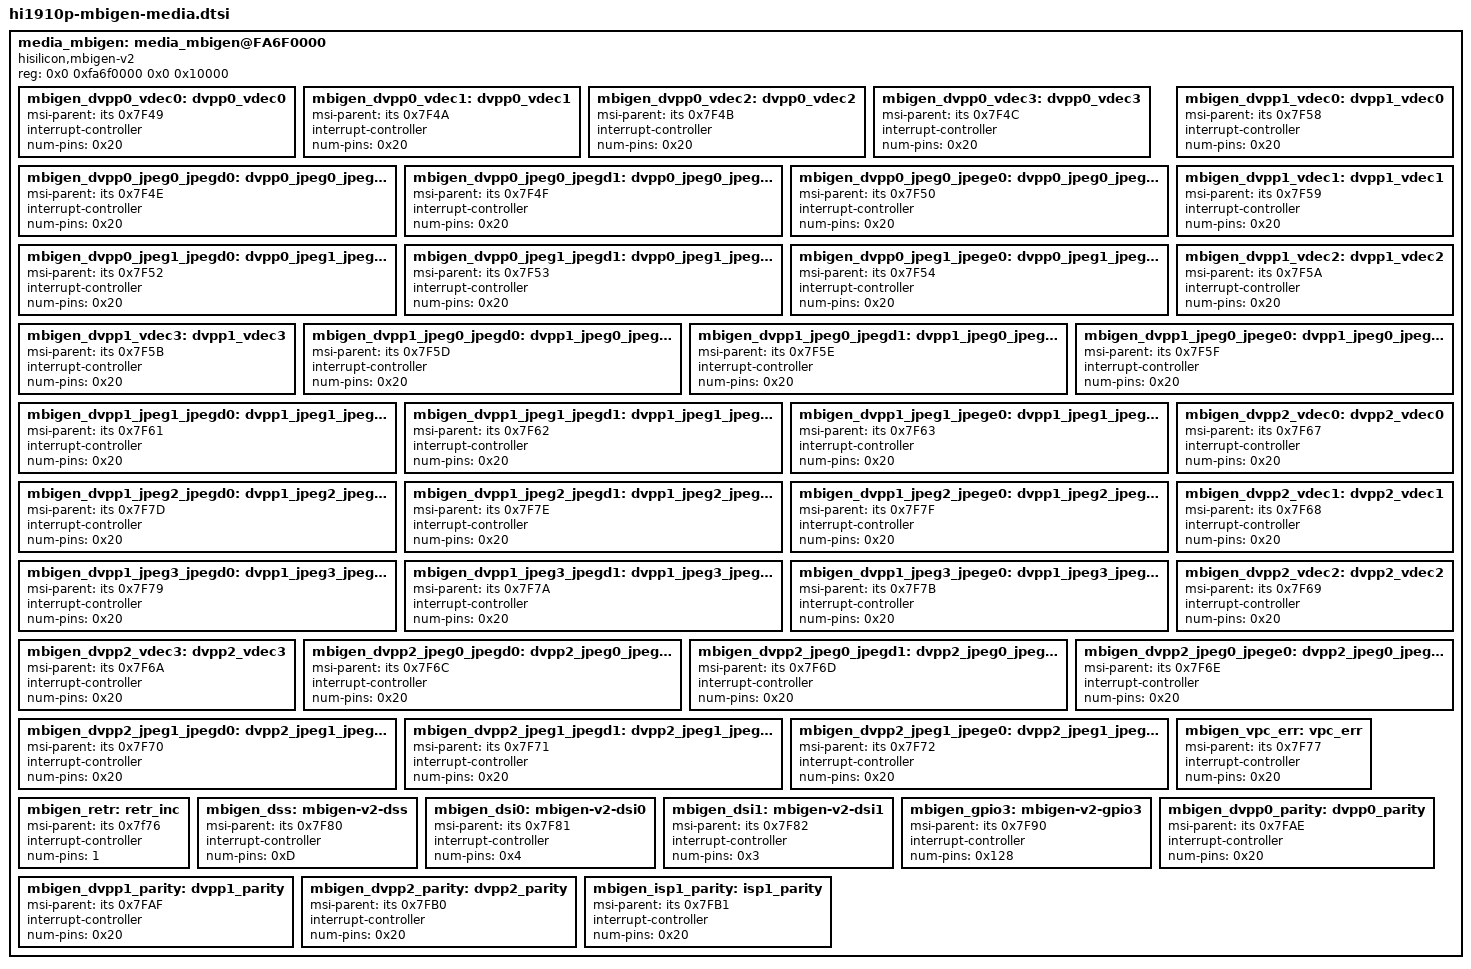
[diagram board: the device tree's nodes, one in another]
/**
* dts file for Hisilicon Ascend Dxxx Development Board
*
* Copyright (C) 2020 Hisilicon Ltd.
*
* This program is free software; you can redistribute it and/or modify
* it under the terms of the GNU General Public License version 2 as
* publishhed by the Free Software Foundation.
*
* Owner：OS
* Author:  c00283067
* Create: Tue Apr 21 20:07:41 EDT 2020
*/
    media_mbigen: media_mbigen@FA6F0000 {
        compatible = "hisilicon,mbigen-v2";
        reg = <0x0 0xfa6f0000 0x0 0x10000>;
        // dvpp 0 vdec
        mbigen_dvpp0_vdec0: dvpp0_vdec0 {
            msi-parent = <&its 0x7F49>;
            interrupt-controller;
            #interrupt-cells = <0x2>;
            num-pins = <0x20>;
        };
        mbigen_dvpp0_vdec1: dvpp0_vdec1 {
            msi-parent = <&its 0x7F4A>;
            interrupt-controller;
            #interrupt-cells = <0x2>;
            num-pins = <0x20>;
        };
        mbigen_dvpp0_vdec2: dvpp0_vdec2 {
            msi-parent = <&its 0x7F4B>;
            interrupt-controller;
            #interrupt-cells = <0x2>;
            num-pins = <0x20>;
        };
        mbigen_dvpp0_vdec3: dvpp0_vdec3 {
            msi-parent = <&its 0x7F4C>;
            interrupt-controller;
            #interrupt-cells = <0x2>;
            num-pins = <0x20>;
        };

        // dvpp 0 jpeg0
        mbigen_dvpp0_jpeg0_jpegd0: dvpp0_jpeg0_jpegd0 {
            msi-parent = <&its 0x7F4E>; // device num: 0x0F5D
            interrupt-controller;
            #interrupt-cells = <0x2>;
            num-pins = <0x20>;
        };
        mbigen_dvpp0_jpeg0_jpegd1: dvpp0_jpeg0_jpegd1 {
            msi-parent = <&its 0x7F4F>; // device num: 0x0F5D
            interrupt-controller;
            #interrupt-cells = <0x2>;
            num-pins = <0x20>;
        };
        mbigen_dvpp0_jpeg0_jpege0: dvpp0_jpeg0_jpege0 {
            msi-parent = <&its 0x7F50>; // device num: 0x0F5F
            interrupt-controller;
            #interrupt-cells = <0x2>;
            num-pins = <0x20>;
        };

        // dvpp 0 jpeg1
        mbigen_dvpp0_jpeg1_jpegd0: dvpp0_jpeg1_jpegd0 {
            msi-parent = <&its 0x7F52>; // device num: 0x0F5D
            interrupt-controller;
            #interrupt-cells = <0x2>;
            num-pins = <0x20>;
        };
        mbigen_dvpp0_jpeg1_jpegd1: dvpp0_jpeg1_jpegd1 {
            msi-parent = <&its 0x7F53>; // device num: 0x0F5D
            interrupt-controller;
            #interrupt-cells = <0x2>;
            num-pins = <0x20>;
        };
        mbigen_dvpp0_jpeg1_jpege0: dvpp0_jpeg1_jpege0 {
            msi-parent = <&its 0x7F54>; // device num: 0x0F5F
            interrupt-controller;
            #interrupt-cells = <0x2>;
            num-pins = <0x20>;
        };

        // dvpp 1 vdec
        mbigen_dvpp1_vdec0: dvpp1_vdec0 {
            msi-parent = <&its 0x7F58>;
            interrupt-controller;
            #interrupt-cells = <0x2>;
            num-pins = <0x20>;
        };
        mbigen_dvpp1_vdec1: dvpp1_vdec1 {
            msi-parent = <&its 0x7F59>;
            interrupt-controller;
            #interrupt-cells = <0x2>;
            num-pins = <0x20>;
        };
        mbigen_dvpp1_vdec2: dvpp1_vdec2 {
            msi-parent = <&its 0x7F5A>;
            interrupt-controller;
            #interrupt-cells = <0x2>;
            num-pins = <0x20>;
        };
        mbigen_dvpp1_vdec3: dvpp1_vdec3 {
            msi-parent = <&its 0x7F5B>;
            interrupt-controller;
            #interrupt-cells = <0x2>;
            num-pins = <0x20>;
        };

        // dvpp1 jpeg0
        mbigen_dvpp1_jpeg0_jpegd0: dvpp1_jpeg0_jpegd0 {
            msi-parent = <&its 0x7F5D>; // device num: 0x0F5D
            interrupt-controller;
            #interrupt-cells = <0x2>;
            num-pins = <0x20>;
        };
        mbigen_dvpp1_jpeg0_jpegd1: dvpp1_jpeg0_jpegd1 {
            msi-parent = <&its 0x7F5E>; // device num: 0x0F5D
            interrupt-controller;
            #interrupt-cells = <0x2>;
            num-pins = <0x20>;
        };
        mbigen_dvpp1_jpeg0_jpege0: dvpp1_jpeg0_jpege0 {
            msi-parent = <&its 0x7F5F>; // device num: 0x0F5F
            interrupt-controller;
            #interrupt-cells = <0x2>;
            num-pins = <0x20>;
        };

        // dvpp 1 jpeg1
        mbigen_dvpp1_jpeg1_jpegd0: dvpp1_jpeg1_jpegd0 {
            msi-parent = <&its 0x7F61>; // device num: 0x0F5D
            interrupt-controller;
            #interrupt-cells = <0x2>;
            num-pins = <0x20>;
        };
        mbigen_dvpp1_jpeg1_jpegd1: dvpp1_jpeg1_jpegd1 {
            msi-parent = <&its 0x7F62>; // device num: 0x0F5D
            interrupt-controller;
            #interrupt-cells = <0x2>;
            num-pins = <0x20>;
        };
        mbigen_dvpp1_jpeg1_jpege0: dvpp1_jpeg1_jpege0 {
            msi-parent = <&its 0x7F63>; // device num: 0x0F5F
            interrupt-controller;
            #interrupt-cells = <0x2>;
            num-pins = <0x20>;
        };

        // dvpp 1 jpeg2
        mbigen_dvpp1_jpeg2_jpegd0: dvpp1_jpeg2_jpegd0 {
            msi-parent = <&its 0x7F7D>; // device num: 0x0F5D
            interrupt-controller;
            #interrupt-cells = <0x2>;
            num-pins = <0x20>;
        };
        mbigen_dvpp1_jpeg2_jpegd1: dvpp1_jpeg2_jpegd1 {
            msi-parent = <&its 0x7F7E>; // device num: 0x0F5D
            interrupt-controller;
            #interrupt-cells = <0x2>;
            num-pins = <0x20>;
        };
        mbigen_dvpp1_jpeg2_jpege0: dvpp1_jpeg2_jpege0 {
            msi-parent = <&its 0x7F7F>; // device num: 0x0F5F
            interrupt-controller;
            #interrupt-cells = <0x2>;
            num-pins = <0x20>;
        };

        // dvpp 1 jpeg3
        mbigen_dvpp1_jpeg3_jpegd0: dvpp1_jpeg3_jpegd0 {
            msi-parent = <&its 0x7F79>; // device num: 0x0F5D
            interrupt-controller;
            #interrupt-cells = <0x2>;
            num-pins = <0x20>;
        };
        mbigen_dvpp1_jpeg3_jpegd1: dvpp1_jpeg3_jpegd1 {
            msi-parent = <&its 0x7F7A>; // device num: 0x0F5D
            interrupt-controller;
            #interrupt-cells = <0x2>;
            num-pins = <0x20>;
        };
        mbigen_dvpp1_jpeg3_jpege0: dvpp1_jpeg3_jpege0 {
            msi-parent = <&its 0x7F7B>; // device num: 0x0F5F
            interrupt-controller;
            #interrupt-cells = <0x2>;
            num-pins = <0x20>;
        };

        // dvpp 2 vdec
        mbigen_dvpp2_vdec0: dvpp2_vdec0 {
            msi-parent = <&its 0x7F67>;
            interrupt-controller;
            #interrupt-cells = <0x2>;
            num-pins = <0x20>;
        };
        mbigen_dvpp2_vdec1: dvpp2_vdec1 {
            msi-parent = <&its 0x7F68>;
            interrupt-controller;
            #interrupt-cells = <0x2>;
            num-pins = <0x20>;
        };
        mbigen_dvpp2_vdec2: dvpp2_vdec2 {
            msi-parent = <&its 0x7F69>;
            interrupt-controller;
            #interrupt-cells = <0x2>;
            num-pins = <0x20>;
        };
        mbigen_dvpp2_vdec3: dvpp2_vdec3 {
            msi-parent = <&its 0x7F6A>;
            interrupt-controller;
            #interrupt-cells = <0x2>;
            num-pins = <0x20>;
        };

        // dvpp2 jpeg0
        mbigen_dvpp2_jpeg0_jpegd0: dvpp2_jpeg0_jpegd0 {
            msi-parent = <&its 0x7F6C>; // device num: 0x0F5D
            interrupt-controller;
            #interrupt-cells = <0x2>;
            num-pins = <0x20>;
        };
        mbigen_dvpp2_jpeg0_jpegd1: dvpp2_jpeg0_jpegd1 {
            msi-parent = <&its 0x7F6D>; // device num: 0x0F5D
            interrupt-controller;
            #interrupt-cells = <0x2>;
            num-pins = <0x20>;
        };
        mbigen_dvpp2_jpeg0_jpege0: dvpp2_jpeg0_jpege0 {
            msi-parent = <&its 0x7F6E>; // device num: 0x0F5F
            interrupt-controller;
            #interrupt-cells = <0x2>;
            num-pins = <0x20>;
        };

        // dvpp 2 jpeg1
        mbigen_dvpp2_jpeg1_jpegd0: dvpp2_jpeg1_jpegd0 {
            msi-parent = <&its 0x7F70>; // device num: 0x0F5D
            interrupt-controller;
            #interrupt-cells = <0x2>;
            num-pins = <0x20>;
        };
        mbigen_dvpp2_jpeg1_jpegd1: dvpp2_jpeg1_jpegd1 {
            msi-parent = <&its 0x7F71>; // device num: 0x0F5D
            interrupt-controller;
            #interrupt-cells = <0x2>;
            num-pins = <0x20>;
        };
        mbigen_dvpp2_jpeg1_jpege0: dvpp2_jpeg1_jpege0 {
            msi-parent = <&its 0x7F72>; // device num: 0x0F5F
            interrupt-controller;
            #interrupt-cells = <0x2>;
            num-pins = <0x20>;
        };

        mbigen_vpc_err: vpc_err {
            msi-parent = <&its 0x7F77>; // device num: 0x0F77
            interrupt-controller;
            #interrupt-cells = <0x2>;
            num-pins = <0x20>;
        };

        mbigen_retr: retr_inc {
            msi-parent = <&its 0x7f76>;
            interrupt-controller;
            #interrupt-cells = <0x2>;
            num-pins = <1>;
        };

        mbigen_dss: mbigen-v2-dss {
            msi-parent = <&its 0x7F80>;
            interrupt-controller;
            #interrupt-cells = <0x2>;
            num-pins = <0xD>;
        };

        mbigen_dsi0: mbigen-v2-dsi0 {
            msi-parent = <&its 0x7F81>;
            interrupt-controller;
            #interrupt-cells = <2>;
            num-pins = <0x4>;
        };

        mbigen_dsi1: mbigen-v2-dsi1 {
            msi-parent = <&its 0x7F82>;
            interrupt-controller;
            #interrupt-cells = <2>;
            num-pins = <0x3>;
        };

        mbigen_gpio3: mbigen-v2-gpio3 {
            msi-parent = <&its 0x7F90>;
            interrupt-controller;
            #interrupt-cells = <2>;
            num-pins = <0x128>;
        };
        mbigen_dvpp0_parity: dvpp0_parity {
            msi-parent = <&its 0x7FAE>;
            interrupt-controller;
            #interrupt-cells = <0x2>;
            num-pins = <0x20>;
        };
        mbigen_dvpp1_parity: dvpp1_parity {
            msi-parent = <&its 0x7FAF>;
            interrupt-controller;
            #interrupt-cells = <0x2>;
            num-pins = <0x20>;
        };
        mbigen_dvpp2_parity: dvpp2_parity {
            msi-parent = <&its 0x7FB0>;
            interrupt-controller;
            #interrupt-cells = <0x2>;
            num-pins = <0x20>;
        };
        mbigen_isp1_parity: isp1_parity {
            msi-parent = <&its 0x7FB1>;
            interrupt-controller;
            #interrupt-cells = <0x2>;
            num-pins = <0x20>;
        };
    };
